VERSION ""

NS_ :

BS_:

BU_: FAN_CTRL CTRL_NODE

BO_ 3221225472 VECTOR__INDEPENDENT_SIG_MSG: 0 Vector__XXX
 SG_ NewSignal_0009 : 32|8@1+ (1,0) [0|0] "" Vector__XXX

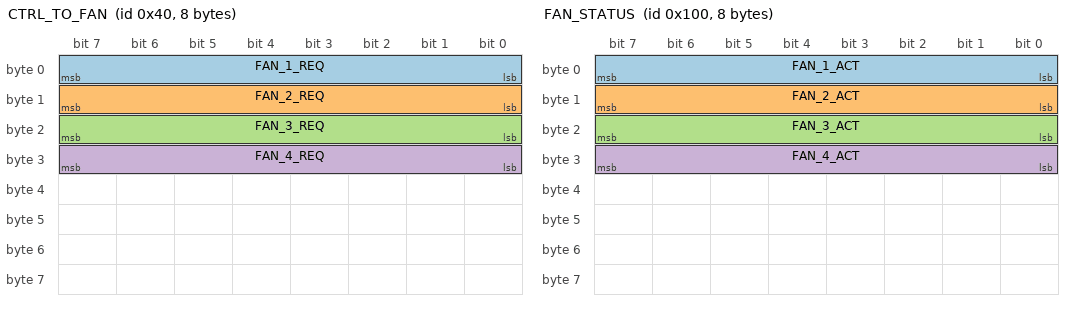
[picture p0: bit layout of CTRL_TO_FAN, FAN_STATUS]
BO_ 64 CTRL_TO_FAN: 8 CTRL_NODE
 SG_ FAN_1_REQ : 0|8@1+ (1,0) [0|100] "%"  FAN_CTRL
 SG_ FAN_2_REQ : 8|8@1+ (1,0) [0|100] "%"  FAN_CTRL
 SG_ FAN_3_REQ : 16|8@1+ (1,0) [0|100] "%"  FAN_CTRL
 SG_ FAN_4_REQ : 24|8@1+ (1,0) [0|100] "%"  FAN_CTRL

BO_ 256 FAN_STATUS: 8 FAN_CTRL
 SG_ FAN_1_ACT : 0|8@1+ (1,0) [0|0] ""  CTRL_NODE
 SG_ FAN_2_ACT : 8|8@1+ (1,0) [0|0] ""  CTRL_NODE
 SG_ FAN_3_ACT : 16|8@1+ (1,0) [0|0] ""  CTRL_NODE
 SG_ FAN_4_ACT : 24|8@1+ (1,0) [0|0] ""  CTRL_NODE

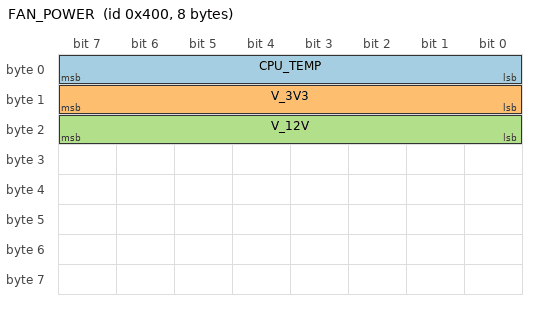
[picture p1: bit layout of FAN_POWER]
BO_ 1024 FAN_POWER: 8 Vector__XXX
 SG_ CPU_TEMP : 0|8@1+ (1,-40) [-40|0] "C" Vector__XXX
 SG_ V_3V3 : 8|8@1+ (0.02,0) [0|0] "V" Vector__XXX
 SG_ V_12V : 16|8@1+ (0.1,0) [0|0] "V" Vector__XXX

BA_DEF_  "BusType" STRING ;
BA_DEF_ BO_  "GenMsgSendType" ENUM  "cyclic","spontaneous";
BA_DEF_ BO_  "GenMsgCycleTime" INT 2 50000;
BA_DEF_DEF_  "BusType" "CAN";
BA_DEF_DEF_  "GenMsgSendType" "cyclic";
BA_DEF_DEF_  "GenMsgCycleTime" 100;
BA_ "GenMsgCycleTime" BO_ 1024 1000;
